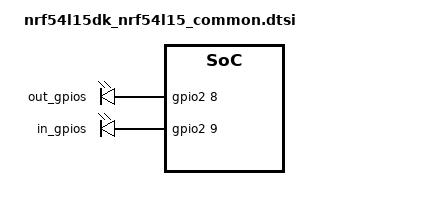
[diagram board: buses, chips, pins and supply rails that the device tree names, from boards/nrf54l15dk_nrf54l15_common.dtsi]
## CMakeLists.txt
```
#
# Copyright (c) 2024 Nordic Semiconductor ASA
#
# SPDX-License-Identifier: LicenseRef-Nordic-5-Clause
#

cmake_minimum_required(VERSION 3.20.0)

find_package(Zephyr REQUIRED HINTS $ENV{ZEPHYR_BASE})
project(gpio_more_loops)

FILE(GLOB app_sources src/main.c)
target_sources(app PRIVATE ${app_sources})
```

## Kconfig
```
# Copyright (c) 2024 Nordic Semiconductor ASA
# SPDX-License-Identifier: LicenseRef-Nordic-5-Clause

config TEST_DURATION
	int "Test duration in ms"
	default 8000
	help
	  Test will run for (at least) defined time.
	  This value affects how many times GPIOs will be toggled.

config CHECK_PULLS
	bool "When enabled, additional check of GPIO pull-up and pull-down is executed."
	default y if BOARD_NRF54H20DK_NRF54H20_CPUAPP

source "Kconfig.zephyr"
```

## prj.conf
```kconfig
CONFIG_GPIO=y
CONFIG_ZTEST=y
CONFIG_LOG=y
```

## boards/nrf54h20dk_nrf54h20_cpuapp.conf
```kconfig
CONFIG_NRF_REGTOOL_VERBOSITY=1
```

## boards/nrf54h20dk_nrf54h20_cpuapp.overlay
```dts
/*
 * Copyright (c) 2024 Nordic Semiconductor ASA
 *
 * SPDX-License-Identifier: LicenseRef-Nordic-5-Clause
 */

/ {
	/* Test requirements:
	 * out-gpios[0] wire connected with in-gpios[0],
	 * out-gpios[1] wire connected with in-gpios[1],
	 * etc.
	 * Output-input GPIO pair must have identical active level flag.
	 */
	test_gpios {
		compatible = "gpio-leds";
		out_gpios: out_gpios {
			gpios = <&gpio0 0 GPIO_ACTIVE_HIGH>, <&gpio2 8 GPIO_ACTIVE_HIGH>,
					<&gpio1 2 GPIO_ACTIVE_HIGH>, <&gpio7 2 GPIO_ACTIVE_HIGH>,
					<&gpio7 6 GPIO_ACTIVE_HIGH>, <&gpio1 5 GPIO_ACTIVE_HIGH>;
		};

		in_gpios: in_gpios {
			gpios = <&gpio0 1 GPIO_ACTIVE_HIGH>, <&gpio2 9 GPIO_ACTIVE_HIGH>,
					<&gpio1 3 GPIO_ACTIVE_HIGH>, <&gpio1 0 GPIO_ACTIVE_HIGH>,
					<&gpio7 7 GPIO_ACTIVE_HIGH>, <&gpio7 1 GPIO_ACTIVE_HIGH>;
		};
	};
};

&gpiote130 {
	status = "okay";
	owned-channels = <7>;
};

&gpio0 {
	status = "okay";
};

&gpio1 {
	status = "okay";
};

&gpio2 {
	status = "okay";
};

&gpio7 {
	status = "okay";
};
```

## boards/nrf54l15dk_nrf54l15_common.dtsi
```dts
/*
 * Copyright (c) 2025 Nordic Semiconductor ASA
 *
 * SPDX-License-Identifier: LicenseRef-Nordic-5-Clause
 */

/ {
	/* Test requirements:
	 * out-gpios[0] wire connected with in-gpios[0],
	 * out-gpios[1] wire connected with in-gpios[1],
	 * etc.
	 * Output-input GPIO pair must have identical active level flag.
	 */
	test_gpios {
		compatible = "gpio-leds";
		out_gpios: out_gpios {
			gpios = <&gpio2 8 GPIO_ACTIVE_HIGH>, <&gpio1 8 GPIO_ACTIVE_HIGH>,
					<&gpio1 10 GPIO_ACTIVE_HIGH>, <&gpio1 12 GPIO_ACTIVE_HIGH>,
					<&gpio2 10 GPIO_ACTIVE_HIGH>;
		};

		in_gpios: in_gpios {
			gpios = <&gpio2 9 GPIO_ACTIVE_HIGH>, <&gpio1 9 GPIO_ACTIVE_HIGH>,
					<&gpio1 11 GPIO_ACTIVE_HIGH>, <&gpio1 13 GPIO_ACTIVE_HIGH>,
					<&gpio1 14 GPIO_ACTIVE_HIGH>;
		};
	};
};

&gpiote20 {
	status = "okay";
};

&gpio1 {
	status = "okay";
};

&gpio2 {
	status = "okay";
};
```

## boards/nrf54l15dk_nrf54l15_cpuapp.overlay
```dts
/*
 * Copyright (c) 2024 Nordic Semiconductor ASA
 *
 * SPDX-License-Identifier: LicenseRef-Nordic-5-Clause
 */

#include "nrf54l15dk_nrf54l15_common.dtsi"
```

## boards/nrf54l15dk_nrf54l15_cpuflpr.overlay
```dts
/*
 * Copyright (c) 2025 Nordic Semiconductor ASA
 *
 * SPDX-License-Identifier: LicenseRef-Nordic-5-Clause
 */

#include "nrf54l15dk_nrf54l15_common.dtsi"
```

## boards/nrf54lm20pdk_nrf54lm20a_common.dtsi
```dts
/*
 * Copyright (c) 2025 Nordic Semiconductor ASA
 *
 * SPDX-License-Identifier: LicenseRef-Nordic-5-Clause
 */

/ {
	/* Test requirements:
	 * out-gpios[0] wire connected with in-gpios[0],
	 * out-gpios[1] wire connected with in-gpios[1],
	 * etc.
	 * Output-input GPIO pair must have identical active level flag.
	 */
	test_gpios {
		compatible = "gpio-leds";
		out_gpios: out_gpios {
			gpios = <&gpio0 3 GPIO_ACTIVE_HIGH>, <&gpio1 30 GPIO_ACTIVE_HIGH>;
		};

		in_gpios: in_gpios {
			gpios = <&gpio1 3 GPIO_ACTIVE_HIGH>, <&gpio1 31 GPIO_ACTIVE_HIGH>;
		};
	};
};

&gpiote20 {
	status = "okay";
};

&gpio0 {
	status = "okay";
};

&gpio1 {
	status = "okay";
};
```

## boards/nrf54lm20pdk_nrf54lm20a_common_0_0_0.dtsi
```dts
/*
 * Copyright (c) 2025 Nordic Semiconductor ASA
 *
 * SPDX-License-Identifier: LicenseRef-Nordic-5-Clause
 */

/ {
	/* Test requirements:
	 * out-gpios[0] wire connected with in-gpios[0],
	 * out-gpios[1] wire connected with in-gpios[1],
	 * etc.
	 * Output-input GPIO pair must have identical active level flag.
	 */
	test_gpios {
		compatible = "gpio-leds";
		out_gpios: out_gpios {
			gpios = <&gpio2 0 GPIO_ACTIVE_HIGH>, <&gpio2 2 GPIO_ACTIVE_HIGH>,
					<&gpio2 4 GPIO_ACTIVE_HIGH>, <&gpio2 6 GPIO_ACTIVE_HIGH>,
					<&gpio1 10 GPIO_ACTIVE_HIGH>;
		};

		in_gpios: in_gpios {
			gpios = <&gpio2 1 GPIO_ACTIVE_HIGH>, <&gpio2 3 GPIO_ACTIVE_HIGH>,
					<&gpio2 5 GPIO_ACTIVE_HIGH>, <&gpio2 7 GPIO_ACTIVE_HIGH>,
					<&gpio1 11 GPIO_ACTIVE_HIGH>;
		};
	};
};

&gpiote20 {
	status = "okay";
};

&gpio1 {
	status = "okay";
};

&gpio2 {
	status = "okay";
};
```

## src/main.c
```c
/*
 * Copyright (c) 2024 Nordic Semiconductor ASA
 *
 * SPDX-License-Identifier: LicenseRef-Nordic-5-Clause
 */

#include <zephyr/logging/log.h>
LOG_MODULE_REGISTER(gpio_loops, LOG_LEVEL_INF);

#include <zephyr/kernel.h>
#include <zephyr/drivers/gpio.h>
#include <zephyr/ztest.h>

#if !DT_NODE_EXISTS(DT_NODELABEL(out_gpios)) || !DT_NODE_EXISTS(DT_NODELABEL(in_gpios))
#error "Unsupported board: test_gpio node is not defined"
#endif

/* Delay after setting GPIO ouputs. It allows signals to settle. */
#define PROPAGATION_DELAY_MS K_MSEC(1U)

/* Delay between GPIO toggle. */
#define TOGGLE_DELAY_MS 500U

const struct gpio_dt_spec out_pins[] = {
	DT_FOREACH_PROP_ELEM_SEP(DT_NODELABEL(out_gpios), gpios, GPIO_DT_SPEC_GET_BY_IDX, (,))
};
const struct gpio_dt_spec in_pins[] = {
	DT_FOREACH_PROP_ELEM_SEP(DT_NODELABEL(in_gpios), gpios, GPIO_DT_SPEC_GET_BY_IDX, (,))
};
BUILD_ASSERT(ARRAY_SIZE(in_pins) == ARRAY_SIZE(out_pins), "mismatched in/out pairs");
const uint8_t npairs = ARRAY_SIZE(in_pins);


/* Check that input GPIOs state match with input parameter 'value'. */
static void _check_inputs(uint32_t value)
{
	bool current;
	bool expected;

	LOG_DBG("_check_inputs(%d)", value);

	/* Wait a bit to stabilize logic level. */
	k_sleep(PROPAGATION_DELAY_MS);

	for (uint8_t i = 0; i < npairs; i++) {
		current = gpio_pin_get_dt(&in_pins[i]);
		expected = value & BIT(i);
		LOG_DBG("_check_inputs L[%d]: current: %d, expected: %d", i, current, expected);
		zassert_equal(current, expected,
			"IN[%d] = %d, while expected %d", i, current, expected);
	}
}

/* Set output GPIOs with gpio_pin_set_dt()
 * and confirm that input GPIOs have expected state.
 */
static void _gpio_pin_set_dt_and_check(uint32_t value)
{
	int out_state;
	int rc;

	LOG_DBG("_gpio_pin_set_dt_and_check(%d)", value);

	for (uint8_t i = 0; i < npairs; i++) {
		out_state = (value & BIT(i)) >> i;
		rc = gpio_pin_set_dt(&out_pins[i], out_state);
		LOG_DBG("_gpio_pin_set_dt_and_check: setting OUT[%d] to %d", i, out_state);
		zassert_equal(rc, 0, "gpio_pin_set_dt(OUT[%d], %d) failed", i, out_state);
	}

	/* Check inputs. */
	_check_inputs(value);
}

/**
 * @brief Test GPIOs are working for CONFIG_TEST_DURATION ms.
 */
ZTEST(gpio_more_loops, test_gpios_are_working)
{
	for (int total_delay = 0; total_delay <= CONFIG_TEST_DURATION;
		total_delay += (2 * TOGGLE_DELAY_MS)) {

		_gpio_pin_set_dt_and_check(0b01010101010101010101010101010101);
		k_msleep(TOGGLE_DELAY_MS);
		_gpio_pin_set_dt_and_check(0b10101010101010101010101010101010);
		k_msleep(TOGGLE_DELAY_MS);
	}
}

static void *suite_setup(void)
{
	uint8_t i;
	int rc;

	TC_PRINT("Test executed on %s\n", CONFIG_BOARD_TARGET);
	TC_PRINT("GPIO Loops count: %d\n", npairs);
	TC_PRINT("===================================================================\n");

	for (i = 0; i < npairs; i++) {
		zassert_true(gpio_is_ready_dt(&in_pins[i]), "IN[%d] is not ready", i);
		zassert_true(gpio_is_ready_dt(&out_pins[i]), "OUT[%d] is not ready", i);

	}

#if defined CONFIG_CHECK_PULLS
	for (i = 0; i < npairs; i++) {
		rc = gpio_pin_configure_dt(&in_pins[i], GPIO_INPUT | GPIO_PULL_UP);
		zassert_equal(rc, 0, "IN[%d] config failed", i);
	}
	_check_inputs(0b11111111111111111111111111111111);
	TC_PRINT("Input pull up works.\n");

	for (i = 0; i < npairs; i++) {
		rc = gpio_pin_configure_dt(&in_pins[i], GPIO_INPUT | GPIO_PULL_DOWN);
		zassert_equal(rc, 0, "IN[%d] config failed", i);
	}
	_check_inputs(0b00000000000000000000000000000000);
	TC_PRINT("Input pull down works.\n");
#endif

	for (i = 0; i < npairs; i++) {
		rc = gpio_pin_configure_dt(&in_pins[i], GPIO_INPUT);
		zassert_equal(rc, 0, "IN[%d] config failed", i);
		rc = gpio_pin_configure_dt(&out_pins[i], GPIO_OUTPUT);
		zassert_equal(rc, 0, "OUT[%d] config failed", i);
		LOG_DBG("IN[%d] - OUT[%d] were configured", i, i);
	}

	return NULL;
}

ZTEST_SUITE(gpio_more_loops, NULL, suite_setup, NULL, NULL, NULL);
```
